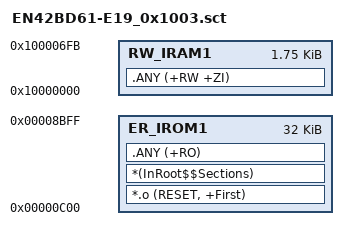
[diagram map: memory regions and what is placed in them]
; *************************************************************
; *** Scatter-Loading Description File generated by uVision ***
; *************************************************************

LR_IROM1 0x00000C00 0x00008000  {    ; load region size_region
  ER_IROM1 0x00000C00 0x00008000  {  ; load address = execution address
   *.o (RESET, +First)
   *(InRoot$$Sections)
   .ANY (+RO)
  }
  RW_IRAM1 0x10000000 0x000006FC  {  ; RW data
   .ANY (+RW +ZI)
  }
}

